# S32R372 register map
Vendor: Freescale Semiconductor, Inc.; Series: Qorivva; File version: 1.6
Registers are 32-bit, read-write, reset 0x0 unless marked. A register's access mark holds for its fields unless they carry their own. Offsets are from the block's base; [hi:lo] are bit positions; 'fields as' and 'values as' point back to an identical list.

## MC_CGM — Unless otherwise noted, all registers may be accessed as 32-bit words, 16-bit half-words, or 8-bit bytes.
Base 0xFFFB0000; register names take the prefix MC_CGM_
0x700 PCS_SDUR 8-bit — PCS Switch Duration Register
  [7:0] SDUR — Switch Duration - This value defines the duration of one PCS clock switch step in terms of IRC_CLK cycles
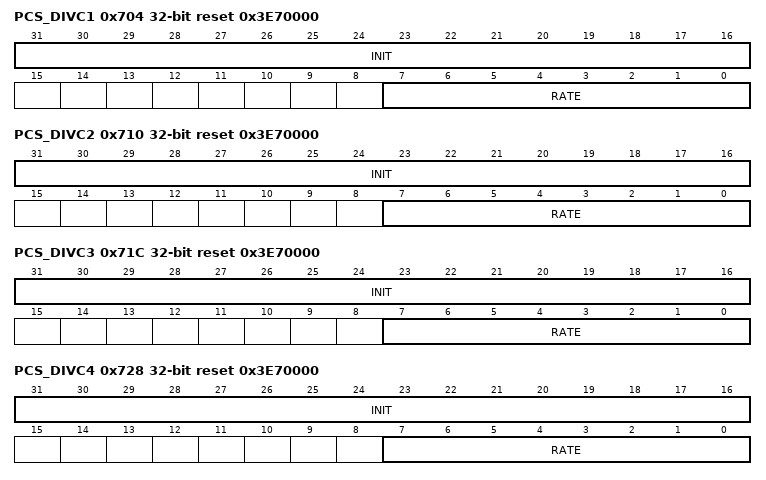
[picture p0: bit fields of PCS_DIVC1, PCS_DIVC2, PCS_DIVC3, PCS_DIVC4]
0x704 PCS_DIVC1 reset 0x3E70000 — PCS Divider Change Register 1
  [31:16] INIT — Divider Change Initial Value - This is initial change value of the clock divider for the clock ramp-up phase when switching to the XOSC_CLK
  [7:0] RATE — Divider Change Rate - This value controls the change value of the clock divider for the clock ramp-up and ramp-down phase when switching to/from the XOSC_CLK
0x708 PCS_DIVE1 reset 0x3E7 — PCS Divider End Register 1
  [19:0] DIVE — Divider End Value - This is the clock divider end value for the clock ramp-down phase when switching from the XOSC_CLK
0x70C PCS_DIVS1 reset 0x3E7 — PCS Divider Start Register 1
  [19:0] DIVS — Divider Start Value - This is the start value of the clock divider for the clock ramp-up phase when switching to the XOSC_CLK
0x710 PCS_DIVC2 reset 0x3E70000 — PCS Divider Change Register 2
  [31:16] INIT — Divider Change Initial Value - This is initial change value of the clock divider for the clock ramp-up phase when switching to the PLL0_PHI_CLK
  [7:0] RATE — Divider Change Rate - This value controls the change value of the clock divider for the clock ramp-up and ramp-down phase when switching to/from the PLL0_PHI_CLK
0x714 PCS_DIVE2 reset 0x3E7 — PCS Divider End Register 2
  [19:0] DIVE — Divider End Value - This is the clock divider end value for the clock ramp-down phase when switching from the PLL0_PHI_CLK
0x718 PCS_DIVS2 reset 0x3E7 — PCS Divider Start Register 2
  [19:0] DIVS — Divider Start Value - This is the start value of the clock divider for the clock ramp-up phase when switching to the PLL0_PHI_CLK
0x71C PCS_DIVC3 reset 0x3E70000 — PCS Divider Change Register 3
  [31:16] INIT — Divider Change Initial Value - This is initial change value of the clock divider for the clock ramp-up phase when switching to the SDPLL_CLK
  [7:0] RATE — Divider Change Rate - This value controls the change value of the clock divider for the clock ramp-up and ramp-down phase when switching to/from the SDPLL_CLK
0x720 PCS_DIVE3 reset 0x3E7 — PCS Divider End Register 3
  [19:0] DIVE — Divider End Value - This is the clock divider end value for the clock ramp-down phase when switching from the SDPLL_CLK
0x724 PCS_DIVS3 reset 0x3E7 — PCS Divider Start Register 3
  [19:0] DIVS — Divider Start Value - This is the start value of the clock divider for the clock ramp-up phase when switching to the SDPLL_CLK
0x728 PCS_DIVC4 reset 0x3E70000 — PCS Divider Change Register 4
  [31:16] INIT — Divider Change Initial Value - This is initial change value of the clock divider for the clock ramp-up phase when switching to the PLL1_PHI_CLK
  [7:0] RATE — Divider Change Rate - This value controls the change value of the clock divider for the clock ramp-up and ramp-down phase when switching to/from the PLL1_PHI_CLK
0x72C PCS_DIVE4 reset 0x3E7 — PCS Divider End Register 4
  [19:0] DIVE — Divider End Value - This is the clock divider end value for the clock ramp-down phase when switching from the PLL1_PHI_CLK
0x730 PCS_DIVS4 reset 0x3E7 — PCS Divider Start Register 4
  [19:0] DIVS — Divider Start Value - This is the start value of the clock divider for the clock ramp-up phase when switching to the PLL1_PHI_CLK
0x7D0 SC_DIV_RC reset 0x1 — System Clock Divider Ratio Change Register
  [0] SYS_DIV_RATIO_CHNG — System Clock Divider Ratio Change
    0=the system clock divider ratios will not change with the next system clock divider configuration update; 1=the system clock divider ratios will change with the next system clock divider configuration update
0x7D4 DIV_UPD_TYPE — Divider Update Type Register
  [31] SYS_UPD_TYPE — System Clock Divider Update Type
    0=The configuration for each system clock divider is updated immediately on writing to the corersponding CGM_SC_DCi register; 1=The configuration for each system clock divider is preloaded on writing to the corersponding CGM_SC_DCi register, and the pre-loaded configurations of all the system clock dividers are updated on writing to the CGM_DIV_UPD_TRIG register
0x7D8 DIV_UPD_TRIG wo — Divider Update Trigger Register
  [31:0] DIV_UPD_TRIGGER — Writing any value to this register will cause all dividers that have corresponding bits set to '1' in the CGM_DIV_UPD_TYPE register and have pre-loaded configurations to be updated immediately
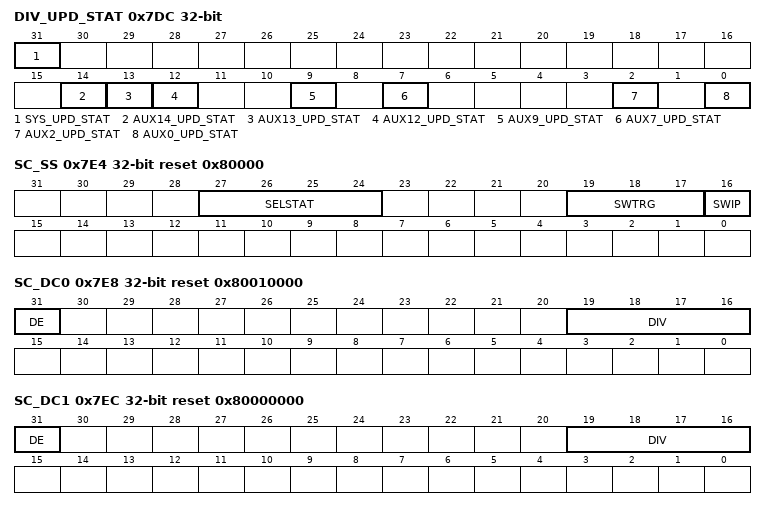
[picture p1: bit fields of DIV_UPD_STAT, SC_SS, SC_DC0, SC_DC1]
0x7DC DIV_UPD_STAT ro — Divider Update Status Register
  [31] SYS_UPD_STAT — System Clock Divider Update Status
    0=no system clock divider configuration updates are in process or divider update has finished; 1=the configuration for at least one system clock divider is being updated
  [14] AUX14_UPD_STAT — Auxiliary Clock 14 Divider Update Status
    0=no Auxillary divider n configuration updates are in process or divider update has finished; 1=the configuration for Auxillary n clock divider is being updated
  [13] AUX13_UPD_STAT — Auxiliary Clock 13 Divider Update Status
    values as AUX14_UPD_STAT
  [12] AUX12_UPD_STAT — Auxiliary Clock 12 Divider Update Status
    values as AUX14_UPD_STAT
  [9] AUX9_UPD_STAT — Auxiliary Clock 9 Divider Update Status
    values as AUX14_UPD_STAT
  [7] AUX7_UPD_STAT — Auxiliary Clock 7 Divider Update Status
    values as AUX14_UPD_STAT
  [2] AUX2_UPD_STAT — Auxiliary Clock 2 Divider Update Status
    values as AUX14_UPD_STAT
  [0] AUX0_UPD_STAT — Auxiliary Clock 0 Divider Update Status
    values as AUX14_UPD_STAT
0x7E4 SC_SS ro reset 0x80000 — System Clock Select Status Register
  [27:24] SELSTAT — System Clock Source Selection Status - This value indicates the current source for the system clock
    0=IRC_CLK; 1=XOSC_CLK; 2=PLL0_PHI_CLK; 4=PLL1_PHI_CLK; 15=system clock is disabled
  [19:17] SWTRG — Switch Trigger cause - This value indicates the cause for the latest clock source switch
    1=switch after request from MC_ME succeeded; 2=switch after request from MC_ME failed due inactive target clock; 3=switch after request from MC_ME failed due inactive current clock; 4=switch to IRC_CLK due to SAFE mode request or reset succeeded; 5=switch to IRC_CLK due to SAFE mode request or reset succeeded, but current clock source was inactive
  [16] SWIP — Switch In Progress
    0=clock source switching has completed; 1=clock source switching is in progress
0x7E8 SC_DC0 reset 0x80010000 — System Clock Divider 0 Configuration Register
  [31] DE — Divider 1 Enable - This divider is always enabled
  [19:16] DIV — Divider 1 Division Value - The resultant SYS_CLK will have a period 'DIV + 1' times that of the system clock
0x7EC SC_DC1 reset 0x80000000 — System Clock Divider 1 Configuration Register
  [31] DE — Divider 1 Enable - This divider is always enabled
  [19:16] DIV — Divider 1 Division Value - The resultant CORE1_CLK will have a period 'DIV + 1' times that of the system clock
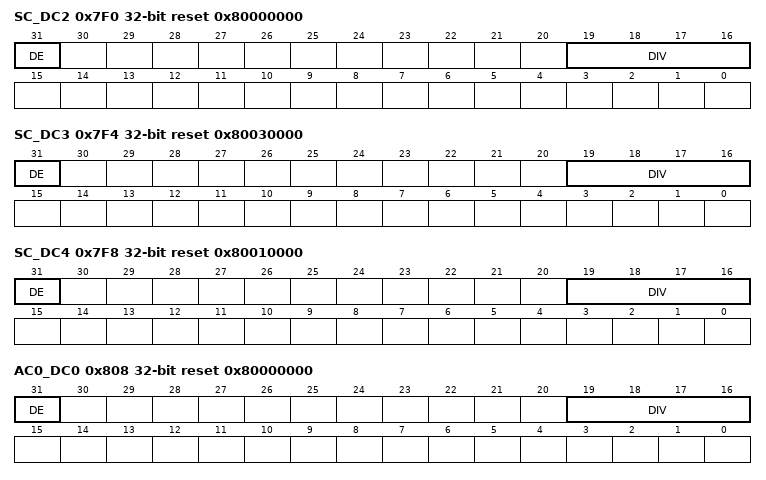
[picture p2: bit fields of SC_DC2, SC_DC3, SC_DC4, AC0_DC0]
0x7F0 SC_DC2 reset 0x80000000 — System Clock Divider 2 Configuration Register
  [31] DE — Divider 1 Enable - This divider is always enabled
  [19:16] DIV — Divider 1 Division Value - The resultant CORE2_CLK will have a period 'DIV + 1' times that of the system clock
0x7F4 SC_DC3 reset 0x80030000 — System Clock Divider 3 Configuration Register
  [31] DE — Divider 1 Enable - This divider is always enabled
  [19:16] DIV — Divider 1 Division Value - The resultant PBRIDGE_n_CLK will have a period 'DIV + 1' times that of the system clock
0x7F8 SC_DC4 reset 0x80010000 — System Clock Divider 4 Configuration Register
  [31] DE — Divider 1 Enable - This divider is always enabled
  [19:16] DIV — Divider 1 Division Value - The resultant DMA_CLK will have a period 'DIV + 1' times that of the system clock
0x800 AC0_SC — Auxiliary Clock 0 Select Control Register
  [26:24] SELCTL — Auxiliary Clock 0 Source Selection Control - Selects the source for auxiliary clock 0.
    0=IRC_CLK; 1=XOSC_CLK; 2=PLL0_PHI_CLK; 3=SDPLL_CLK; 4=PLL1_PHI_CLK
0x804 AC0_SS ro — Auxiliary Clock 0 Select Status Register
  [26:24] SELSTAT — Auxiliary Clock 0 Source Selection Status - This value indicates the current source for auxiliary clock 0
    values as AC0_SC.SELCTL
0x808 AC0_DC0 reset 0x80000000 — Auxiliary Clock 0 Divider 0 Configuration Register
  [31] DE — Divider Enable
    0=Disable auxiliary clock 0 divider 0; 1=Enable auxiliary clock 0 divider 0
  [19:16] DIV — Divider Division Value - The resultant MC_CLK will have a period 'DIV + 1' times that of auxiliary clock 0
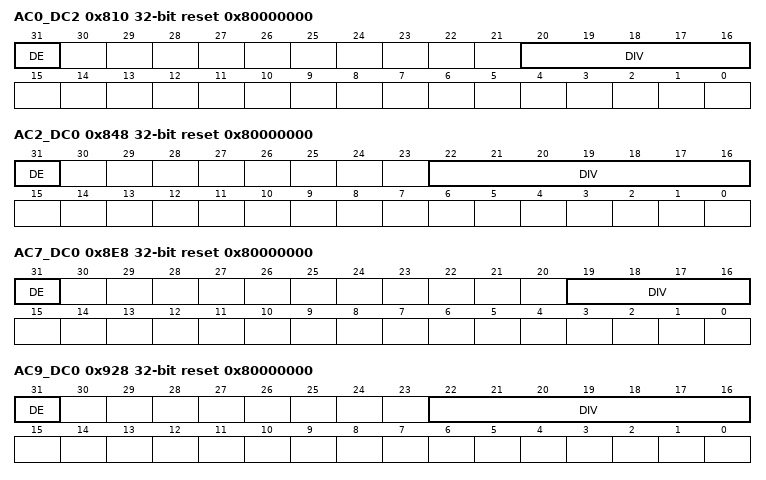
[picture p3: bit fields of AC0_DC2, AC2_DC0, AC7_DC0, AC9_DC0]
0x810 AC0_DC2 reset 0x80000000 — Auxiliary Clock 0 Divider 2 Configuration Register
  [31] DE — Divider Enable
    0=Disable auxiliary clock 0 divider 2; 1=Enable auxiliary clock 0 divider 2
  [20:16] DIV — Divider Division Value - The resultant ADC_CLK will have a period 'DIV + 1' times that of the system clock
0x840 AC2_SC — Auxiliary Clock 2 Select Control Register
  [26:24] SELCTL — Auxiliary Clock 2 Source Selection Control - This value selects the current source for auxiliary clock 2
    values as AC0_SC.SELCTL
0x844 AC2_SS ro — Auxiliary Clock 2 Select Status Register
  [26:24] SELSTAT — Auxiliary Clock 2 Source Selection Status - This value indicates the current source for the CAN clock
    values as AC0_SC.SELCTL
0x848 AC2_DC0 reset 0x80000000 — Auxiliary Clock 2 Divider 0 Configuration Register
  [31] DE — Divider Enable
    0=Disable auxiliary clock 2 divider 0; 1=Enable auxiliary clock 2 divider 0
  [22:16] DIV — Divider Division Value - The resultant CAN0_CLK will have a period 'DIV + 1' times that of the auxiliary clock 2
0x860 AC3_SC — Auxiliary Clock 3 Select Control Register
  [24] SELCTL — Auxiliary Clock 3 Source Selection Control - This value selects the current source for auxiliary clock 3
    0=IRC_CLK; 1=XOSC_CLK
0x864 AC3_SS ro — Auxiliary Clock 3 Select Status Register
  [24] SELSTAT — Auxiliary Clock 3 Source Selection Status - This value indicates the current source for auxiliary clock 3
    0=IRC_CLK; 1=XOSC_CLK
0x880 AC4_SC — Auxiliary Clock 4 Select Control Register
  [24] SELCTL — Auxiliary Clock 4 Source Selection Control - This value selects the current source for auxiliary clock 4
    0=PLL0_PHI1_CLK; 1=XOSC_CLK
0x884 AC4_SS ro — Auxiliary Clock 4 Select Status Register
  [24] SELSTAT — Auxiliary Clock 4 Source Selection Status - This value indicates the current source for auxiliary clock 4
    0=PLL0_PHI1_CLK; 1=XOSC_CLK
0x8E0 AC7_SC — Auxiliary Clock 7 Select Control Register
  [26:24] SELCTL — Auxiliary Clock 7 Source Selection Control - This value selects the current source for auxiliary clock 7
    values as AC0_SC.SELCTL
0x8E4 AC7_SS ro — Auxiliary Clock 7 Select Status Register
  [26:24] SELSTAT — Auxiliary Clock 7 Source Selection Status - This value indicates the current source for auxiliary clock 7
    values as AC0_SC.SELCTL
0x8E8 AC7_DC0 reset 0x80000000 — Auxiliary Clock 7 Divider 0 Configuration Register
  [31] DE — Divider Enable
    0=Disable auxiliary clock 7 divider 0; 1=Enable auxiliary clock 7 divider 0
  [19:16] DIV — Divider Division Value - The resultant SPT_CLK will have a period 'DIV + 1' times that of the auxiliary clock 7
0x928 AC9_DC0 reset 0x80000000 — Auxiliary Clock 9 Divider 0 Configuration Register
  [31] DE — Divider Enable
    0=Disable auxiliary clock 9 divider 0; 1=Enable auxiliary clock 9 divider 0
  [22:16] DIV — Divider Division Value - The resultant CLK_OUT1 will have a period 'DIV + 1' times that of the auxiliary clock 9
0x980 AC12_SC — Auxiliary Clock 12 Select Control Register
  [26:24] SELCTL — Auxiliary Clock 12 Source Selection Control - This value selects the current source for auxiliary clock 12
    values as AC0_SC.SELCTL
0x984 AC12_SS ro — Auxiliary Clock 12 Select Status Register
  [26:24] SELSTAT — Auxiliary Clock 12 Source Selection Status - This value indicates the current source for auxiliary clock 12
    values as AC0_SC.SELCTL
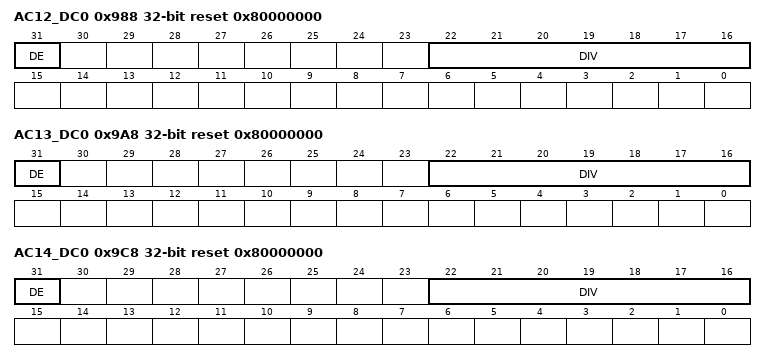
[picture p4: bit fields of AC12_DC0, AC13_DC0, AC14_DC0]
0x988 AC12_DC0 reset 0x80000000 — Auxiliary Clock 12 Divider 0 Configuration Register
  [31] DE — Divider Enable
    0=Disable auxiliary clock 12 divider 0; 1=Enable auxiliary clock 12 divider 0
  [22:16] DIV — Divider Division Value - The resultant SPI_CLK will have a period 'DIV + 1' times that of the auxiliary clock 12
0x9A0 AC13_SC — Auxiliary Clock 13 Select Control Register
  [26:24] SELCTL — Auxiliary Clock 13 Source Selection Control - This value selects the current source for auxiliary clock 13
    0=IRC_CLK; 1=XOSC_CLK; 2=PLL0_PHI_CLK; 3=SDPLL_CLK; 4=PLL1_PHI_CLK; 5=MC_CLK; 6=PBRIDGE_0_CLK
0x9A4 AC13_SS ro — Auxiliary Clock 13 Select Status Register
  [26:24] SELSTAT — Auxiliary Clock 13 Source Selection Status - This value indicates the current source for auxiliary clock 13
    values as AC13_SC.SELCTL
0x9A8 AC13_DC0 reset 0x80000000 — Auxiliary Clock 13 Divider 0 Configuration Register
  [31] DE — Divider Enable
    0=Disable auxiliary clock 13 divider 0; 1=Enable auxiliary clock 13 divider 0
  [22:16] DIV — Divider Division Value - The resultant LIN_CLK will have a period 'DIV + 1' times that of the auxiliary clock 13
0x9C8 AC14_DC0 reset 0x80000000 — Auxiliary Clock 14 Divider 0 Configuration Register
  [31] DE — Divider Enable
    0=Disable auxiliary clock 14 divider 0; 1=Enable auxiliary clock 14 divider 0
  [22:16] DIV — Divider Division Value - The resultant CLK_OUT0 will have a period 'DIV + 1' times that of the auxiliary clock 14
